# FM33G0XX register map
File version: 1.0
CPU: SC000 r1p0, little endian, no MPU, no FPU, 3 interrupt priority bits
Registers are 32-bit, read-write, reset 0x0 unless marked. A register's access mark holds for its fields unless they carry their own. Offsets are from the block's base; [hi:lo] are bit positions; {n}, {i} and the like mark numbered series.

## I2C — I2C Registers
Base 0x40012400
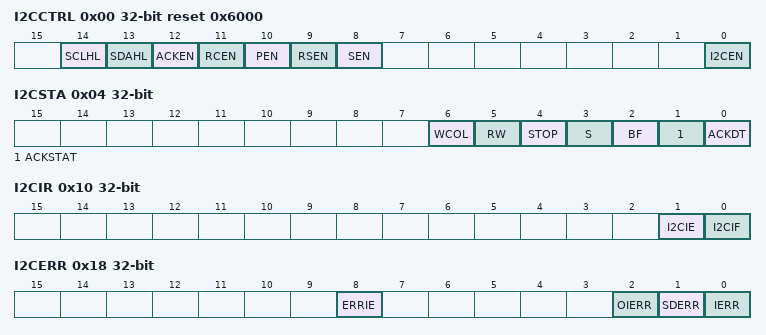
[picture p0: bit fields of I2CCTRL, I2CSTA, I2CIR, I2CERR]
0x00 I2CCTRL reset 0x6000 — I2C CONTROL REGISTER
  [14] SCLHL — SCL PULL HIGH AT I2C DISABLE
  [13] SDAHL — SDA PULL HIGH AT I2C DISABLE
  [12] ACKEN — AUTO ACK ENABLE AT MASTER
  [11] RCEN — RECEIVE ENABLE
  [10] PEN — STOP SEQUENCE ENABLE
  [9] RSEN — REPEAT SYART ENABLE
  [8] SEN — START SEQUENCE ENABLE
  [0] I2CEN
0x04 I2CSTA — I2C STATUS
  [6] WCOL — write collision
  [5] RW ro — BUSY
  [4] STOP ro — detect stop sequence
  [3] S ro — detect start sequence
  [2] BF ro — BUFF FULL
    0=EMPTY (SSPBUF EMPTY); 1=FULL (SSPBUF FULL)
  [1] ACKSTAT — ACK STATE FROM SLAVE
    0=RACK0 (RECEIVE ACK 0 FROM SLAVE); 1=RACKN (RECEIVE ACK NONE FROM SLAVE)
  [0] ACKDT — MASTER RESPOND NONE
    0=MRP0 (MASTER RESPOND 0); 1=MRPN (MASTER RESPOND NONE)
0x08 I2CBRG reset 0x13 — I2C BAUDRATE
  [8:0] I2CBRG — Baud = FAPBCLK/((BRG+1)MUL4)
0x0C I2CBUF
  [7:0] I2CBUF
0x10 I2CIR — I2C INTERRUPT REGISTER
  [1] I2CIE
  [0] I2CIF — I2C IF,write 1 to clear
0x14 I2CFSM
  [3:0] I2CFSM
    0=IDLE; 1=START1; 2=START2; 3=START_DONE; 4=TX_STATE; 5=RCACK; 6=OP_IDLE; 7=STOP1; 8=STOP2; 9=STOP_DONE; 10=RTP_START; 11=RX_STATE; 12=ACT_STATE; 13=STOP0
0x18 I2CERR
  [8] ERRIE
  [2] OIERR — OP_IDLE ERR
  [1] SDERR — START_DONE ERR
  [0] IERR — IDLE ERR

## ANAC — ANAC Registers
Base 0x40012800
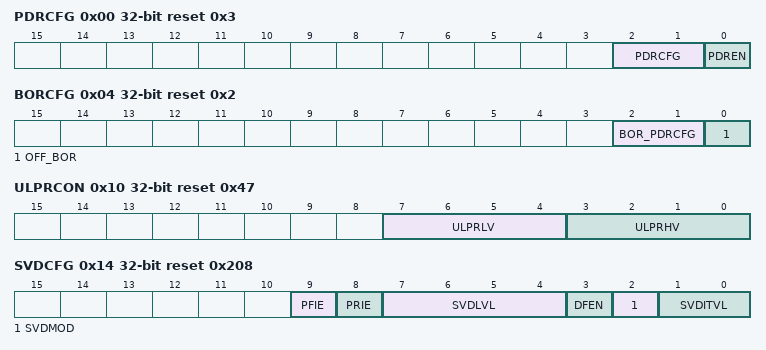
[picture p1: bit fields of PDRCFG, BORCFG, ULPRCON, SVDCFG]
0x00 PDRCFG reset 0x3 — PDR CONFIG REGISTER
  [2:1] PDRCFG — PDR CONFIG
    0=1.5V; 1=1.25V; 2=1.35V; 3=1.4V
  [0] PDREN — PDR ENABLE
0x04 BORCFG reset 0x2 — BOR CONFIG
  [2:1] BOR_PDRCFG — BOR_PDR CONFIG
    0=1.7V; 1=1.6V; 2=1.65V; 3=1.75V
  [0] OFF_BOR
0x08 LDO15CON reset 0x7 — LDO15 CONTROL REGISTER
  [3:0] TRIM_LDO15 — LDO15 TRIM DATA
0x0C VREFTRIM reset 0x1A
  [5:0] VREFTRIM — VREF TRIM DATA
0x10 ULPRCON reset 0x47 — ULP CONFIG REGISTER
  [7:4] ULPRLV — ULPLDO LOW VOLTAGE OUTPUT
  [3:0] ULPRHV — ULPLDO HIGH VOLTAGE OUTPUT
0x14 SVDCFG reset 0x208 — SVD CONFIG REGISTER
  [9] PFIE — Power Fail Interrupt Enable
  [8] PRIE — Power Restore Interrupt Enable
  [7:4] SVDLVL — SVD ALARM LEVEL
  [3] DFEN — SVD DIGITAL FILTER ENABLE
  [2] SVDMOD — SVD MODE
    0=IMTEN (INTERMITTENT ENABLE); 1=OFTEN (OFTEN ENABLE)
  [1:0] SVDITVL — SVD Interval
    0=15.625ms; 1=62.5ms; 2=256ms; 3=1s
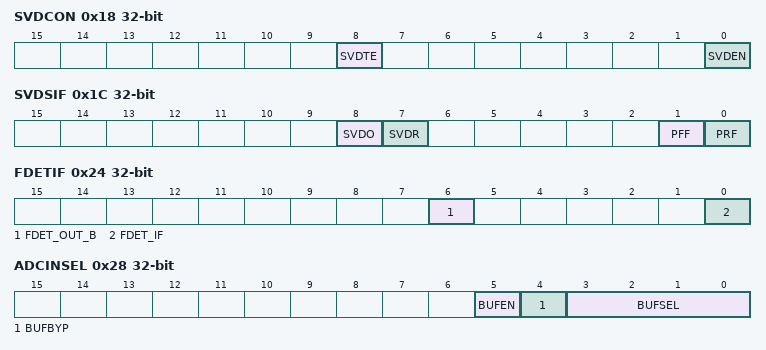
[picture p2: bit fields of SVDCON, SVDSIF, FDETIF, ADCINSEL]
0x18 SVDCON — SVD CONTROL REGISTER
  [8] SVDTE — SVD TEST EENABLE
  [0] SVDEN — SVD ENABLE
0x1C SVDSIF — SVD STATUS AND IF
  [8] SVDO ro — SVD OUTPUT
  [7] SVDR ro — SVD OUTPUT LATCH
  [1] PFF
  [0] PRF
0x20 FDETIE — XTLF FREQ DETECT IE
  [0] LFDET_IE
0x24 FDETIF — XTLF FREQ DETECT IF
  [6] FDET_OUT_B, [0] FDET_IF
0x28 ADCINSEL — ADCIN SELECT REGISTER
  [5] BUFEN — BUF ENABLE
  [4] BUFBYP
  [3:0] BUFSEL — ADCIN SELECT
    0=vbe1_adc; 1=vbe2_adc; 2=vbe3_adc; 3=vcmbuf_adc; 4=vddx; 5=lfdet_out_b; 6=VDD50; 7=VREF08; {v}=AN{v-7} (v=8..15)
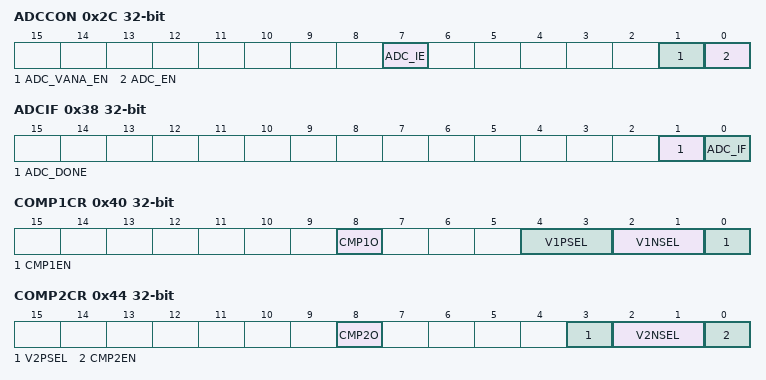
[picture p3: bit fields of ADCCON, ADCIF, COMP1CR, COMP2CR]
0x2C ADCCON — ADC CONTROL REGISTER
  [7] ADC_IE
  [1] ADC_VANA_EN — ADC OUTER VOLTAGE TEST ENABLE
  [0] ADC_EN — ADC ENABLE
0x30 ADCTRIM
  [10:0] ADC_TRIM
0x34 ADCDATA ro
  [10:0] ADC_DATA rw
0x38 ADCIF
  [1] ADC_DONE ro — ADC_DONE IF,disable ADC to clear
  [0] ADC_IF — ADC IF,write 1 to clear
0x3C TRNGCON — TRNG CONTROL REGISTER
  [0] RNGEN
0x40 COMP1CR — COMP1 CONTROL REGISTER
  [8] CMP1O ro — CMP1 OUTPUT
  [4:3] V1PSEL
    0=PF6; 1=PF2; 2=PG2; 3=PG3
  [2:1] V1NSEL
    0=PF5; 1=PF1; 2=Vref 0.8V; 3=Vref/2 0.4V
  [0] CMP1EN
0x44 COMP2CR — COMP2 CONTROL REGISTER
  [8] CMP2O — CMP2 OUTPUT
  [3] V2PSEL
    0=PC15; 1=PE4
  [2:1] V2NSEL
    0=PC14; 1=PE3; 2=Vref 0.8V; 3=Vref/2 0.4V
  [0] CMP2EN — CMP2 ENABLE
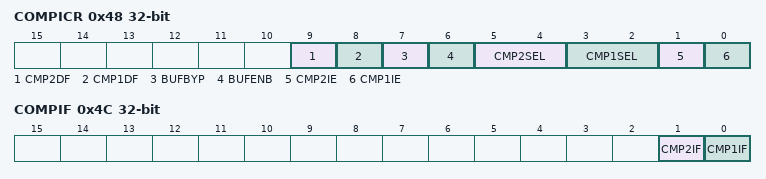
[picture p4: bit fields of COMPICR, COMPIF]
0x48 COMPICR — COMP INT CONFIG REGISTER
  [9] CMP2DF
  [8] CMP1DF
  [7] BUFBYP
  [6] BUFENB
  [5:4] CMP2SEL — CMP2 INT SOURCE SELECT
  [3:2] CMP1SEL — CMP1 INT SOURCE SELECT
  [1] CMP2IE
  [0] CMP1IE
0x4C COMPIF
  [1] CMP2IF — CMP2IF,WRITE 1 TO CLEAR
  [0] CMP1IF — CMP1IF, WRITE 1 TO CLEAR
